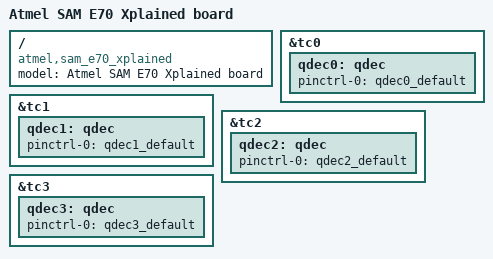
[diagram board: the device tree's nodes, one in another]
/*
 * Copyright (c) 2017 Piotr Mienkowski
 * Copyright (c) 2017 Justin Watson
 * Copyright (c) 2020-2024 Gerson Fernando Budke <nandojve@gmail.com>
 *
 * SPDX-License-Identifier: Apache-2.0
 */

/dts-v1/;

#include <atmel/same70q21.dtsi>
#include "sam_e70_xplained-common.dtsi"

/ {
	model = "Atmel SAM E70 Xplained board";
	compatible = "atmel,sam_e70_xplained", "atmel,same70q21", "atmel,same70";
};

&tc0 {
	qdec0: qdec {
		pinctrl-0 = <&qdec0_default>;
		pinctrl-names = "default";
	};
};

&tc1 {
	qdec1: qdec {
		pinctrl-0 = <&qdec1_default>;
		pinctrl-names = "default";
	};
};

&tc2 {
	qdec2: qdec {
		pinctrl-0 = <&qdec2_default>;
		pinctrl-names = "default";
	};
};

&tc3 {
	qdec3: qdec {
		pinctrl-0 = <&qdec3_default>;
		pinctrl-names = "default";
	};
};
